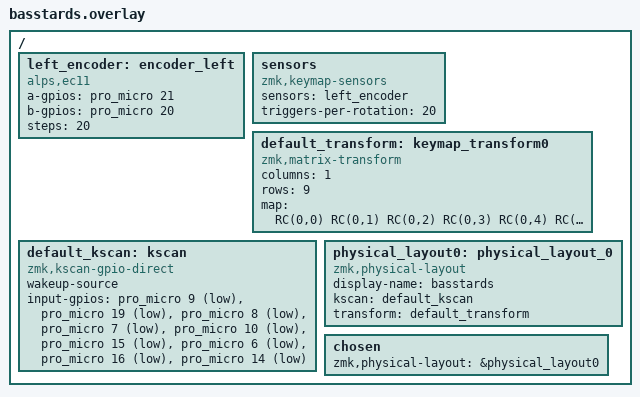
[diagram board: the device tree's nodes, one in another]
#include <dt-bindings/zmk/matrix_transform.h> // Put this with the other includes at the top of your
#include <physical_layouts.dtsi>

/ {    
    left_encoder: encoder_left {
    	compatible = "alps,ec11";
    	a-gpios = <&pro_micro 21 (GPIO_ACTIVE_HIGH | GPIO_PULL_UP)>;
    	b-gpios = <&pro_micro 20 (GPIO_ACTIVE_HIGH | GPIO_PULL_UP)>;
    	steps = <20>;
    	status = "okay";
    };
    
    sensors: sensors {
    	compatible = "zmk,keymap-sensors";
    	sensors = <&left_encoder>;
    	triggers-per-rotation = <20>;
    };
    
    default_transform: keymap_transform0 {
        compatible = "zmk,matrix-transform";
        columns = <1>;
        rows = <9>;
        map = <
            RC(0,0) RC(0,1) RC(0,2) RC(0,3) RC(0,4) RC(0,5) RC(0,6) RC(0,7) RC(0,8)
        >;
    };
    
    default_kscan: kscan {
        compatible = "zmk,kscan-gpio-direct";
        wakeup-source;
        input-gpios = <&pro_micro 9 (GPIO_ACTIVE_LOW | GPIO_PULL_UP)>,
                    <&pro_micro 19 (GPIO_ACTIVE_LOW | GPIO_PULL_UP)>,
                    <&pro_micro 8 (GPIO_ACTIVE_LOW | GPIO_PULL_UP)>,
                    <&pro_micro 7 (GPIO_ACTIVE_LOW | GPIO_PULL_UP)>,
                    <&pro_micro 10 (GPIO_ACTIVE_LOW | GPIO_PULL_UP)>,
                    <&pro_micro 15 (GPIO_ACTIVE_LOW | GPIO_PULL_UP)>,
                    <&pro_micro 6 (GPIO_ACTIVE_LOW | GPIO_PULL_UP)>,
                    <&pro_micro 16 (GPIO_ACTIVE_LOW | GPIO_PULL_UP)>,
                    <&pro_micro 14 (GPIO_ACTIVE_LOW | GPIO_PULL_UP)>;
    };
    
    physical_layout0: physical_layout_0 { 
        compatible = "zmk,physical-layout";
        display-name = "basstards";
        kscan = <&default_kscan>; // Label of the kscan node, optional if all layouts use the same
        transform = <&default_transform>; // Label of the matrix transform for this layout
    };
    
    chosen {
        zmk,physical-layout = &physical_layout0;
        // Other chosen items
    };
};


